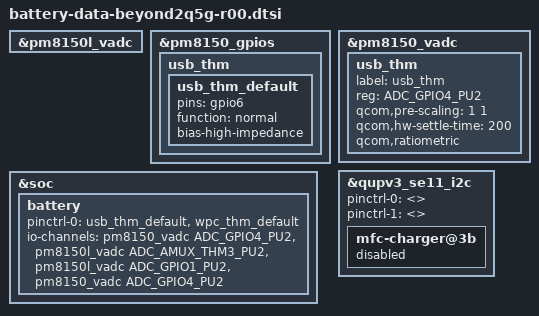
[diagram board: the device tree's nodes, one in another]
/*
 * SAMSUNG board device tree source
 *
 * Copyright (c) 2018 Samsung Electronics Co., Ltd.
 *		http://www.samsung.com
 *
 * This program is free software; you can redistribute it and/or modify
 * it under the terms of the GNU General Public License version 2 as
 * published by the Free Software Foundation.
 */

/* This dtsi is for hw rev from 00 to 03 */
#include "battery-data-beyond2q5g-common.dtsi"

&pm8150l_vadc {
	/delete-node/ usb_thm;
};

&pm8150_gpios {
	usb_thm { /* GPIO_06 */
		usb_thm_default: usb_thm_default {
			pins = "gpio6";
			function = "normal";
			bias-high-impedance;
		};
	};
};

&pm8150_vadc {
	usb_thm { /* GPIO_06 */
		label = "usb_thm";
		reg = <ADC_GPIO4_PU2>;
		qcom,pre-scaling = <1 1>;
		qcom,hw-settle-time = <200>;
		qcom,ratiometric;
	};
};

&qupv3_se11_i2c { 
	pinctrl-0 = <>;
	pinctrl-1 = <>;

	mfc-charger@3b {
		status = "disabled";
	};
};

&soc {
	battery {
		/delete-property/ battery,wireless_charger_name;
		/delete-property/ battery,wpc_det;
		/delete-property/ battery,wpc_en;

		pinctrl-0 = <&usb_thm_default &wpc_thm_default>;

		io-channels = <&pm8150_vadc ADC_GPIO4_PU2>, <&pm8150l_vadc ADC_AMUX_THM3_PU2>, <&pm8150l_vadc ADC_GPIO1_PU2>, <&pm8150_vadc ADC_GPIO4_PU2>;
	};
};
